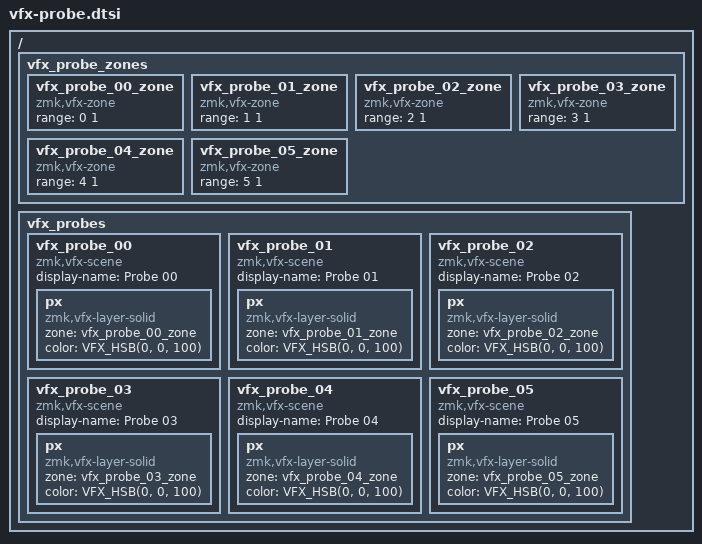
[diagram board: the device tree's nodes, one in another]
/*
 * Temporary diagnostic: which of the six underglow LEDs is which.
 *
 * Everything else about this board's wiring is settled. These six answer to
 * no key, so nothing about normal use reveals their order, and they are the
 * one part of the chain still inferred rather than measured.
 *
 * Each scene lights exactly one of them. They sit on the glow channel, so
 * stepping that channel walks them one at a time: hold the Mouse layer with
 * right shift and press next, noting which LED comes up each time.
 *
 * Delete this file, its #include in both overlays, and the six probe scenes
 * in the glow channel lists once that is written down.
 */

#include <dt-bindings/zmk/vfx.h>

/ {
    vfx_probe_zones {
        vfx_probe_00_zone: vfx_probe_00_zone {
            compatible = "zmk,vfx-zone";
            range = <0 1>;
        };
        vfx_probe_01_zone: vfx_probe_01_zone {
            compatible = "zmk,vfx-zone";
            range = <1 1>;
        };
        vfx_probe_02_zone: vfx_probe_02_zone {
            compatible = "zmk,vfx-zone";
            range = <2 1>;
        };
        vfx_probe_03_zone: vfx_probe_03_zone {
            compatible = "zmk,vfx-zone";
            range = <3 1>;
        };
        vfx_probe_04_zone: vfx_probe_04_zone {
            compatible = "zmk,vfx-zone";
            range = <4 1>;
        };
        vfx_probe_05_zone: vfx_probe_05_zone {
            compatible = "zmk,vfx-zone";
            range = <5 1>;
        };
    };

    vfx_probes {
        vfx_probe_00: vfx_probe_00 {
            compatible = "zmk,vfx-scene";
            display-name = "Probe 00";

            px {
                compatible = "zmk,vfx-layer-solid";
                zone = <&vfx_probe_00_zone>;
                color = <VFX_HSB(0, 0, 100)>;
            };
        };
        vfx_probe_01: vfx_probe_01 {
            compatible = "zmk,vfx-scene";
            display-name = "Probe 01";

            px {
                compatible = "zmk,vfx-layer-solid";
                zone = <&vfx_probe_01_zone>;
                color = <VFX_HSB(0, 0, 100)>;
            };
        };
        vfx_probe_02: vfx_probe_02 {
            compatible = "zmk,vfx-scene";
            display-name = "Probe 02";

            px {
                compatible = "zmk,vfx-layer-solid";
                zone = <&vfx_probe_02_zone>;
                color = <VFX_HSB(0, 0, 100)>;
            };
        };
        vfx_probe_03: vfx_probe_03 {
            compatible = "zmk,vfx-scene";
            display-name = "Probe 03";

            px {
                compatible = "zmk,vfx-layer-solid";
                zone = <&vfx_probe_03_zone>;
                color = <VFX_HSB(0, 0, 100)>;
            };
        };
        vfx_probe_04: vfx_probe_04 {
            compatible = "zmk,vfx-scene";
            display-name = "Probe 04";

            px {
                compatible = "zmk,vfx-layer-solid";
                zone = <&vfx_probe_04_zone>;
                color = <VFX_HSB(0, 0, 100)>;
            };
        };
        vfx_probe_05: vfx_probe_05 {
            compatible = "zmk,vfx-scene";
            display-name = "Probe 05";

            px {
                compatible = "zmk,vfx-layer-solid";
                zone = <&vfx_probe_05_zone>;
                color = <VFX_HSB(0, 0, 100)>;
            };
        };
    };
};
